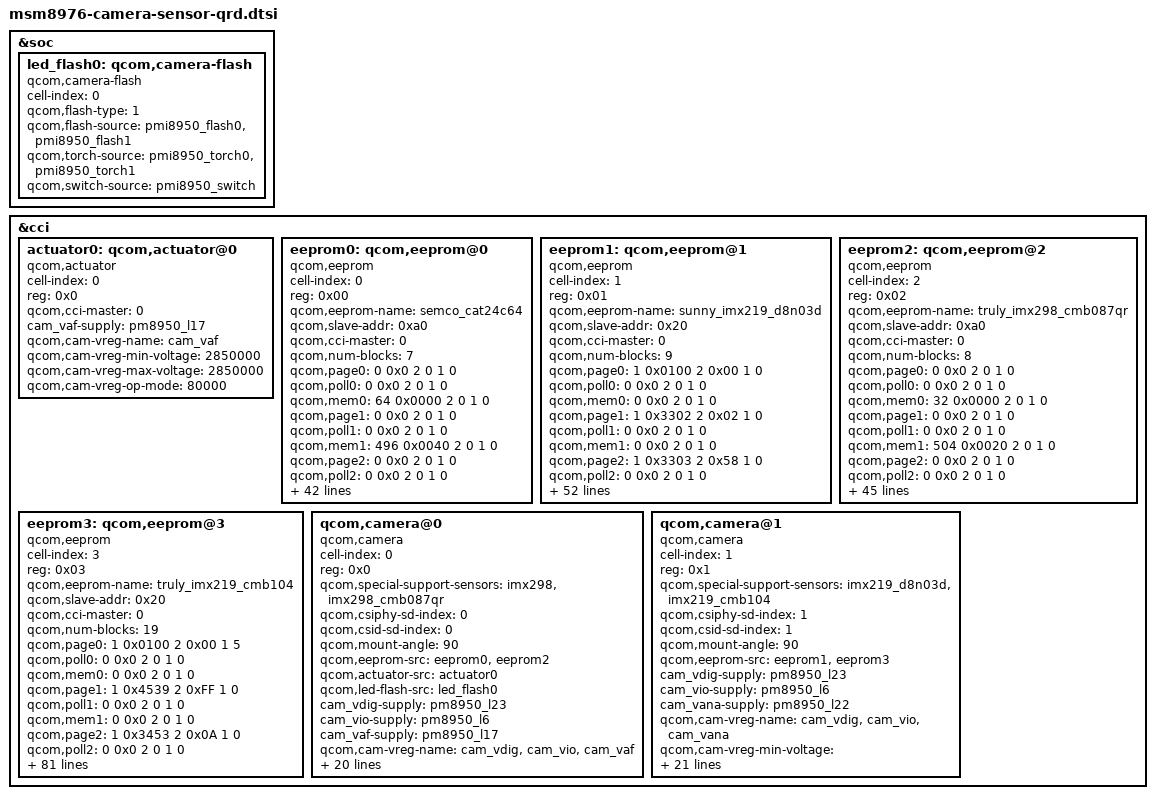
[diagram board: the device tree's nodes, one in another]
/*
 * Copyright (c) 2015-2016, The Linux Foundation. All rights reserved.
 *
 * This program is free software; you can redistribute it and/or modify
 * it under the terms of the GNU General Public License version 2 and
 * only version 2 as published by the Free Software Foundation.
 *
 * This program is distributed in the hope that it will be useful,
 * but WITHOUT ANY WARRANTY; without even the implied warranty of
 * MERCHANTABILITY or FITNESS FOR A PARTICULAR PURPOSE.  See the
 * GNU General Public License for more details.
 */

&soc {
	led_flash0: qcom,camera-flash {
		cell-index = <0>;
		compatible = "qcom,camera-flash";
		qcom,flash-type = <1>;
		qcom,flash-source = <&pmi8950_flash0 &pmi8950_flash1>;
		qcom,torch-source = <&pmi8950_torch0 &pmi8950_torch1>;
		qcom,switch-source = <&pmi8950_switch>;
	};
};

&cci {
	actuator0: qcom,actuator@0 {
		cell-index = <0>;
		reg = <0x0>;
		compatible = "qcom,actuator";
		qcom,cci-master = <0>;
		cam_vaf-supply = <&pm8950_l17>;
		qcom,cam-vreg-name = "cam_vaf";
		qcom,cam-vreg-min-voltage = <2850000>;
		qcom,cam-vreg-max-voltage = <2850000>;
		qcom,cam-vreg-op-mode = <80000>;
	};

	eeprom0: qcom,eeprom@0{
		cell-index = <0>;
		reg = <0x00>;
		qcom,eeprom-name = "semco_cat24c64";
		compatible = "qcom,eeprom";
		qcom,slave-addr = <0xa0>;
		qcom,cci-master = <0>;
		qcom,num-blocks = <7>;

		qcom,page0 = <0 0x0 2 0 1 0>;
		qcom,poll0 = <0 0x0 2 0 1 0>;
		qcom,mem0 = <64 0x0000 2 0 1 0>;
		qcom,page1 = <0 0x0 2 0 1 0>;
		qcom,poll1 = <0 0x0 2 0 1 0>;
		qcom,mem1 = <496 0x0040 2 0 1 0>;
		qcom,page2 = <0 0x0 2 0 1 0>;
		qcom,poll2 = <0 0x0 2 0 1 0>;
		qcom,mem2 = <496 0x0230 2 0 1 0>;
		qcom,page3 = <0 0x0 2 0 1 0>;
		qcom,poll3 = <0 0x0 2 0 1 0>;
		qcom,mem3 = <496 0x0420 2 0 1 0>;
		qcom,page4 = <0 0x0 2 0 1 0>;
		qcom,poll4 = <0 0x0 2 0 1 0>;
		qcom,mem4 = <496 0x0610 2 0 1 0>;
		qcom,page5 = <0 0x0 2 0 1 0>;
		qcom,poll5 = <0 0x0 2 0 1 0>;
		qcom,mem5 = <256 0x0800 2 0 1 0>;
		qcom,page6 = <0 0x0 2 0 1 0>;
		qcom,poll6 = <0 0x0 2 0 1 0>;
		qcom,mem6 = <98 0x0900 2 0 1 0>;

		cam_vdig-supply = <&pm8950_l23>;
		cam_vio-supply = <&pm8950_l6>;
		qcom,cam-vreg-name = "cam_vdig", "cam_vio";
		qcom,cam-vreg-min-voltage = <1200000 0>;
		qcom,cam-vreg-max-voltage = <1200000 0>;
		qcom,cam-vreg-op-mode = <200000 0>;
		pinctrl-names = "cam_default", "cam_suspend";
		pinctrl-0 = <&cam_sensor_mclk0_default
				&cam_sensor_rear_default>;
		pinctrl-1 = <&cam_sensor_mclk0_sleep &cam_sensor_rear_sleep>;
		gpios = <&msm_gpio 26 0>,
			<&msm_gpio 129 0>,
			<&msm_gpio 123 0>;
		qcom,gpio-standby = <1>;
		qcom,gpio-vana = <2>;
		qcom,gpio-req-tbl-num = <0 1 2>;
		qcom,gpio-req-tbl-flags = <1 0 0>;
		qcom,gpio-req-tbl-label = "MCAM1_MCLK0",
			"MCAM1_STANDBY",
			"MCAM1_VANA";			

		qcom,cam-power-seq-type = "sensor_vreg",
			"sensor_gpio", "sensor_vreg",
			"sensor_clk",
			"sensor_gpio";
		qcom,cam-power-seq-val = "cam_vio",
			"sensor_gpio_vana", "cam_vdig",
			"sensor_cam_mclk",
			"sensor_gpio_standby";
		qcom,cam-power-seq-cfg-val = <1 1 1 24000000 1>;
		qcom,cam-power-seq-delay = <0 0 1 5 10>;
		status = "ok";
		clocks = <&clock_gcc clk_mclk0_clk_src>,
				<&clock_gcc clk_gcc_camss_mclk0_clk>;
		clock-names = "cam_src_clk", "cam_clk";
		qcom,i2c-freq-mode = <0>;
		qcom,clock-rates = <24000000 0>;
	};

	eeprom1: qcom,eeprom@1{
		cell-index = <1>;
		reg = <0x01>;
		qcom,eeprom-name = "sunny_imx219_d8n03d";
		compatible = "qcom,eeprom";
		qcom,slave-addr = <0x20>;
		qcom,cci-master = <0>;

		qcom,num-blocks = <9>;
		qcom,page0 = <1 0x0100 2 0x00 1 0>;//Standby mode
		qcom,poll0 = <0 0x0 2 0 1 0>;
		qcom,mem0 = <0 0x0 2 0 1 0>;

		qcom,page1 = <1 0x3302 2 0x02 1 0>;//set OTP write clock setting
		qcom,poll1 = <0 0x0 2 0 1 0>;
		qcom,mem1 = <0 0x0 2 0 1 0>;

		qcom,page2 = <1 0x3303 2 0x58 1 0>;//set OTP write clock setting
		qcom,poll2 = <0 0x0 2 0 1 0>;
		qcom,mem2 = <0 0x0 2 0 1 0>;

		qcom,page3 = <1 0x012A 2 0x18 1 0>;//set input clock frequency
		qcom,poll3 = <0 0x0 2 0 1 0>;
		qcom,mem3 = <0 0x0 2 0 1 0>;

		qcom,page4 = <1 0x012B 2 0x00 1 0>;//set input clock frequency
		qcom,poll4 = <0 0x0 2 0 1 0>;
		qcom,mem4 = <0 0x0 2 0 1 0>;

		qcom,page5 = <1 0x3300 2 0x08 1 0>;//ECC OFF
		qcom,poll5 = <0 0x0 2 0 1 0>;
		qcom,mem5 = <0 0x0 2 0 1 0>;

		qcom,page6 = <1 0x3200 2 0x01 1 1>;//Page Read Enable
		qcom,poll6 = <1 0x3201 2 0x01 1 100>;//wait until ready to read
		qcom,mem6 = <0 0x0 2 0 1 0>;

		qcom,page7 = <1 0x3202 2 0x00 1 1>;//set page number=0
		qcom,poll7 = <0 0x3201 2 0x01 1 100>;
		qcom,mem7 = <64 0x3204 2 0 1 1>;//read page 0

		qcom,page8 = <1 0x3202 2 0x01 1 1>;//set page number=1
		qcom,poll8 = <0 0x3201 2 0x01 1 100>;
		qcom,mem8 = <64 0x3204 2 0 1 1>;//read page 1

		cam_vdig-supply = <&pm8950_l23>;
		cam_vio-supply = <&pm8950_l6>;
		cam_vana-supply = <&pm8950_l22>;
		qcom,cam-vreg-name = "cam_vdig", "cam_vio", "cam_vana";
		qcom,cam-vreg-min-voltage = <1200000 1800000 2800000>;
		qcom,cam-vreg-max-voltage = <1200000 1800000 2800000>;
		qcom,cam-vreg-op-mode = <105000 80000 80000>;
		qcom,gpio-no-mux = <0>;
		pinctrl-names = "cam_default", "cam_suspend";
		pinctrl-0 = <&cam_sensor_mclk1_default &cam_sensor_front_default>;
		pinctrl-1 = <&cam_sensor_mclk1_sleep &cam_sensor_front_sleep>;
		gpios = <&msm_gpio 28 0>,
			<&msm_gpio 131 0>;
		qcom,gpio-standby = <1>;
		qcom,gpio-req-tbl-num = <0 1>;
		qcom,gpio-req-tbl-flags = <1 0>;
		qcom,gpio-req-tbl-label = "MCAM1_MCLK2",
					  "MCAM1_STANDBY2";

		qcom,cam-power-seq-type = "sensor_vreg",
			"sensor_vreg", "sensor_vreg",
			"sensor_clk", "sensor_gpio";
		qcom,cam-power-seq-val = "cam_vio",
			"cam_vana", "cam_vdig",
			"sensor_cam_mclk",
			"sensor_gpio_standby";
		qcom,cam-power-seq-cfg-val = <1 1 1 24000000 1>;
		qcom,cam-power-seq-delay = <0 0 1 10 1>;
		status = "ok";
		clocks = <&clock_gcc clk_mclk2_clk_src>,
			<&clock_gcc clk_gcc_camss_mclk2_clk>;
		clock-names = "cam_src_clk", "cam_clk";
		qcom,i2c-freq-mode = <0>;
		qcom,clock-rates = <24000000 0>;
	};


	eeprom2: qcom,eeprom@2{
		cell-index = <2>;
		reg = <0x02>;
		qcom,eeprom-name = "truly_imx298_cmb087qr";
		compatible = "qcom,eeprom";
		qcom,slave-addr = <0xa0>;
		qcom,cci-master = <0>;
		qcom,num-blocks = <8>;

		qcom,page0 = <0 0x0 2 0 1 0>;
		qcom,poll0 = <0 0x0 2 0 1 0>;
		qcom,mem0 = <32 0x0000 2 0 1 0>;
		qcom,page1 = <0 0x0 2 0 1 0>;
		qcom,poll1 = <0 0x0 2 0 1 0>;
		qcom,mem1 = <504 0x0020 2 0 1 0>;
		qcom,page2 = <0 0x0 2 0 1 0>;
		qcom,poll2 = <0 0x0 2 0 1 0>;
		qcom,mem2 = <504 0x0218 2 0 1 0>;
		qcom,page3 = <0 0x0 2 0 1 0>;
		qcom,poll3 = <0 0x0 2 0 1 0>;
		qcom,mem3 = <504 0x0410 2 0 1 0>;
		qcom,page4 = <0 0x0 2 0 1 0>;
		qcom,poll4 = <0 0x0 2 0 1 0>;
		qcom,mem4 = <504 0x0608 2 0 1 0>;
		qcom,page5 = <0 0x0 2 0 1 0>;
		qcom,poll5 = <0 0x0 2 0 1 0>;
		qcom,mem5 = <256 0x0800 2 0 1 0>;
		qcom,page6 = <0 0x0 2 0 1 0>;
		qcom,poll6 = <0 0x0 2 0 1 0>;
		qcom,mem6 = <354 0x0900 2 0 1 0>;
		qcom,page7 = <0 0x0 2 0 1 0>;
		qcom,poll7 = <0 0x0 2 0 1 0>;
		qcom,mem7 = <98 0x0A62 2 0 1 0>;

		cam_vdig-supply = <&pm8950_l23>;
		cam_vio-supply = <&pm8950_l6>;
		qcom,cam-vreg-name = "cam_vdig", "cam_vio";
		qcom,cam-vreg-min-voltage = <1200000 0>;
		qcom,cam-vreg-max-voltage = <1200000 0>;
		qcom,cam-vreg-op-mode = <200000 0>;
		pinctrl-names = "cam_default", "cam_suspend";
		pinctrl-0 = <&cam_sensor_mclk0_default
				&cam_sensor_rear_default>;
		pinctrl-1 = <&cam_sensor_mclk0_sleep &cam_sensor_rear_sleep>;
		gpios = <&msm_gpio 26 0>,
			<&msm_gpio 129 0>,
			<&msm_gpio 123 0>;
		qcom,gpio-standby = <1>;
		qcom,gpio-vana = <2>;
		qcom,gpio-req-tbl-num = <0 1 2>;
		qcom,gpio-req-tbl-flags = <1 0 0>;
		qcom,gpio-req-tbl-label = "MCAM1_MCLK0",
			"MCAM1_STANDBY",
			"MCAM1_VANA";

		qcom,cam-power-seq-type = "sensor_vreg",
			"sensor_gpio", "sensor_vreg",
			"sensor_clk",
			"sensor_gpio";
		qcom,cam-power-seq-val = "cam_vio",
			"sensor_gpio_vana", "cam_vdig",
			"sensor_cam_mclk",
			"sensor_gpio_standby";
		qcom,cam-power-seq-cfg-val = <1 1 1 24000000 1>;
		qcom,cam-power-seq-delay = <0 0 1 5 10>;
		status = "ok";
		clocks = <&clock_gcc clk_mclk0_clk_src>,
				<&clock_gcc clk_gcc_camss_mclk0_clk>;
		clock-names = "cam_src_clk", "cam_clk";
		qcom,i2c-freq-mode = <0>;
		qcom,clock-rates = <24000000 0>;
	};


	eeprom3: qcom,eeprom@3{
		cell-index = <3>;
		reg = <0x03>;
		qcom,eeprom-name = "truly_imx219_cmb104";
		compatible = "qcom,eeprom";
		qcom,slave-addr = <0x20>;
		qcom,cci-master = <0>;
		qcom,num-blocks = <19>;

		qcom,page0 = <1 0x0100 2 0x00 1 5>;//Standby mode
		qcom,poll0 = <0 0x0 2 0 1 0>;
		qcom,mem0 = <0 0x0 2 0 1 0>;

		qcom,page1 = <1 0x4539 2 0xFF 1 0>;// Set Monitor output
		qcom,poll1 = <0 0x0 2 0 1 0>;
		qcom,mem1 = <0 0x0 2 0 1 0>;

		qcom,page2 = <1 0x3453 2 0x0A 1 0>;// Set Monitor output
		qcom,poll2 = <0 0x0 2 0 1 0>;
		qcom,mem2 = <0 0x0 2 0 1 0>;

		qcom,page3 = <1 0x3302 2 0x02 1 0>;//set OTP write clock setting
		qcom,poll3 = <0 0x0 2 0 1 0>;
		qcom,mem3 = <0 0x0 2 0 1 0>;

		qcom,page4 = <1 0x3303 2 0x58 1 0>;//set OTP write clock setting
		qcom,poll4 = <0 0x0 2 0 1 0>;
		qcom,mem4 = <0 0x0 2 0 1 0>;

		qcom,page5 = <1 0x012A 2 0x18 1 0>;//set input clock frequency
		qcom,poll5 = <0 0x0 2 0 1 0>;
		qcom,mem5 = <0 0x0 2 0 1 0>;

		qcom,page6 = <1 0x012B 2 0x00 1 0>;//set input clock frequency
		qcom,poll6 = <0 0x0 2 0 1 0>;
		qcom,mem6 = <0 0x0 2 0 1 0>;

		qcom,page7 = <1 0x3300 2 0x08 1 0>;//ECC OFF
		qcom,poll7 = <0 0x0 2 0 1 0>;
		qcom,mem7 = <0 0x0 2 0 1 0>;

		qcom,page8 = <1 0x3200 2 0x01 1 30>;//Page Read Enable
		qcom,poll8 = <0 0x3201 2 0x01 1 100>;//wait until ready to read
		qcom,mem8 = <0 0x0 2 0 1 0>;

		qcom,page9 = <1 0x3202 2 0x01 1 5>;//set page number=1
		qcom,poll9 = <0 0x3201 2 0x01 1 100>;
		qcom,mem9 = <64 0x3204 2 0 1 2>;//read page 1

		qcom,page10 = <1 0x3202 2 0x02 1 5>;//set page number=2
		qcom,poll10 = <0 0x3201 2 0x01 1 100>;
		qcom,mem10 = <64 0x3204 2 0 1 2>;//read page 2

		qcom,page11 = <1 0x3202 2 0x03 1 5>;//lsc data as follows
		qcom,poll11 = <0 0x3201 2 0x01 1 100>;
		qcom,mem11 = <64 0x3204 2 0 1 2>;

		qcom,page12 = <1 0x3202 2 0x04 1 5>;
		qcom,poll12 = <0 0x3201 2 0x01 1 100>;
		qcom,mem12 = <64 0x3204 2 0 1 2>;

		qcom,page13 = <1 0x3202 2 0x05 1 5>;
		qcom,poll13 = <0 0x3201 2 0x01 1 100>;
		qcom,mem13 = <64 0x3204 2 0 1 2>;

		qcom,page14 = <1 0x3202 2 0x06 1 5>;
		qcom,poll14 = <0 0x3201 2 0x01 1 100>;
		qcom,mem14 = <64 0x3204 2 0 1 2>;

		qcom,page15 = <1 0x3202 2 0x07 1 5>;
		qcom,poll15 = <0 0x3201 2 0x01 1 100>;
		qcom,mem15 = <64 0x3204 2 0 1 2>;

		qcom,page16 = <1 0x3202 2 0x08 1 5>;
		qcom,poll16 = <0 0x3201 2 0x01 1 100>;
		qcom,mem16 = <64 0x3204 2 0 1 2>;

		qcom,page17 = <1 0x3202 2 0x09 1 5>;
		qcom,poll17 = <0 0x3201 2 0x01 1 100>;
		qcom,mem17 = <64 0x3204 2 0 1 2>;

		qcom,page18 = <1 0x3202 2 0x0A 1 5>;
		qcom,poll18 = <0 0x3201 2 0x01 1 100>;
		qcom,mem18 = <64 0x3204 2 0 1 2>;

		cam_vdig-supply = <&pm8950_l23>;
		cam_vio-supply = <&pm8950_l6>;
		cam_vana-supply = <&pm8950_l22>;
		qcom,cam-vreg-name = "cam_vdig", "cam_vio", "cam_vana";
		qcom,cam-vreg-min-voltage = <1200000 1800000 2800000>;
		qcom,cam-vreg-max-voltage = <1200000 1800000 2800000>;
		qcom,cam-vreg-op-mode = <200000 80000 100000>;
		pinctrl-names = "cam_default", "cam_suspend";
		pinctrl-0 = <&cam_sensor_mclk1_default &cam_sensor_front_default>;
		pinctrl-1 = <&cam_sensor_mclk1_sleep &cam_sensor_front_sleep>;
		gpios = <&msm_gpio 28 0>,
			<&msm_gpio 131 0>;
		qcom,gpio-standby = <1>;
		qcom,gpio-req-tbl-num = <0 1>;
		qcom,gpio-req-tbl-flags = <1 0>;
		qcom,gpio-req-tbl-label = "MCAM1_MCLK2",
			"MCAM1_STANDBY2";

		qcom,cam-power-seq-type = "sensor_vreg",
			"sensor_vreg", "sensor_vreg",
			"sensor_clk", "sensor_gpio";
		qcom,cam-power-seq-val = "cam_vio",
			"cam_vana", "cam_vdig",
			"sensor_cam_mclk",
			"sensor_gpio_standby";
		qcom,cam-power-seq-cfg-val = <1 1 1 24000000 1>;
		qcom,cam-power-seq-delay = <0 0 1 10 1>;
		status = "ok";
		clocks = <&clock_gcc clk_mclk2_clk_src>,
				<&clock_gcc clk_gcc_camss_mclk2_clk>;
		clock-names = "cam_src_clk", "cam_clk";
		qcom,i2c-freq-mode = <0>;
		qcom,clock-rates = <24000000 0>;
	};

	qcom,camera@0 {
		cell-index = <0>;
		compatible = "qcom,camera";
		reg = <0x0>;
		qcom,special-support-sensors = "imx298","imx298_cmb087qr";
		qcom,csiphy-sd-index = <0>;
		qcom,csid-sd-index = <0>;
		qcom,mount-angle = <90>;
		qcom,eeprom-src = <&eeprom0 &eeprom2>;
		qcom,actuator-src = <&actuator0>;
		qcom,led-flash-src = <&led_flash0>;
		cam_vdig-supply = <&pm8950_l23>;
		cam_vio-supply = <&pm8950_l6>;
		cam_vaf-supply = <&pm8950_l17>;
		qcom,cam-vreg-name = "cam_vdig", "cam_vio", "cam_vaf";
		qcom,cam-vreg-min-voltage = <1200000 0  2850000>;
		qcom,cam-vreg-max-voltage = <1200000 0  2850000>;
		qcom,cam-vreg-op-mode = <200000 0  100000>;
		pinctrl-names = "cam_default", "cam_suspend";
		pinctrl-0 = <&cam_sensor_mclk0_default
				&cam_sensor_rear_default>;
		pinctrl-1 = <&cam_sensor_mclk0_sleep &cam_sensor_rear_sleep>;
		gpios = <&msm_gpio 26 0>,
			<&msm_gpio 129 0>,
			<&msm_gpio 123 0>;
		qcom,gpio-standby = <1>;
		qcom,gpio-vana = <2>;
		qcom,gpio-req-tbl-num = <0 1 2>;
		qcom,gpio-req-tbl-flags = <1 0 0>;
		qcom,gpio-req-tbl-label = "MCAM1_MCLK0",
			"MCAM1_STANDBY",
			"MCAM1_VANA";

		qcom,sensor-position = <0>;
		qcom,sensor-mode = <0>;
		qcom,cci-master = <0>;
		status = "ok";
		clocks = <&clock_gcc clk_mclk0_clk_src>,
				<&clock_gcc clk_gcc_camss_mclk0_clk>;
		clock-names = "cam_src_clk", "cam_clk";
		qcom,clock-rates = <24000000 0>;
	};
	qcom,camera@1 {
		cell-index = <1>;
		compatible = "qcom,camera";
		reg = <0x1>;
		qcom,special-support-sensors = "imx219_d8n03d","imx219_cmb104";
		qcom,csiphy-sd-index = <1>;
		qcom,csid-sd-index = <1>;
		qcom,mount-angle = <90>;
		qcom,eeprom-src = <&eeprom1 &eeprom3>;
		cam_vdig-supply = <&pm8950_l23>;
		cam_vio-supply = <&pm8950_l6>;
		cam_vana-supply = <&pm8950_l22>;
		qcom,cam-vreg-name = "cam_vdig", "cam_vio",
							"cam_vana";
		qcom,cam-vreg-min-voltage = <1200000 1800000 2800000>;
		qcom,cam-vreg-max-voltage = <1200000 1800000 2800000>;
		qcom,cam-vreg-op-mode = <200000 80000 100000>;
		qcom,gpio-no-mux = <0>;
		pinctrl-names = "cam_default", "cam_suspend";
		pinctrl-0 = <&cam_sensor_mclk1_default &cam_sensor_front_default>;
		pinctrl-1 = <&cam_sensor_mclk1_sleep &cam_sensor_front_sleep>;
		gpios = <&msm_gpio 28 0>,
			<&msm_gpio 131 0>;
		qcom,gpio-standby = <1>;
		qcom,gpio-req-tbl-num = <0 1 >;
		qcom,gpio-req-tbl-flags = <1 0 >;
		qcom,gpio-req-tbl-label = "MCAM1_MCLK2",
			"MCAM1_STANDBY2";
		qcom,sensor-position = <1>;
		qcom,sensor-mode = <0>;
		qcom,cci-master = <0>;
		status = "ok";
		clocks = <&clock_gcc clk_mclk2_clk_src>,
				<&clock_gcc clk_gcc_camss_mclk2_clk>;
		clock-names = "cam_src_clk", "cam_clk";
		qcom,clock-rates = <24000000 0>; 
	};
};
